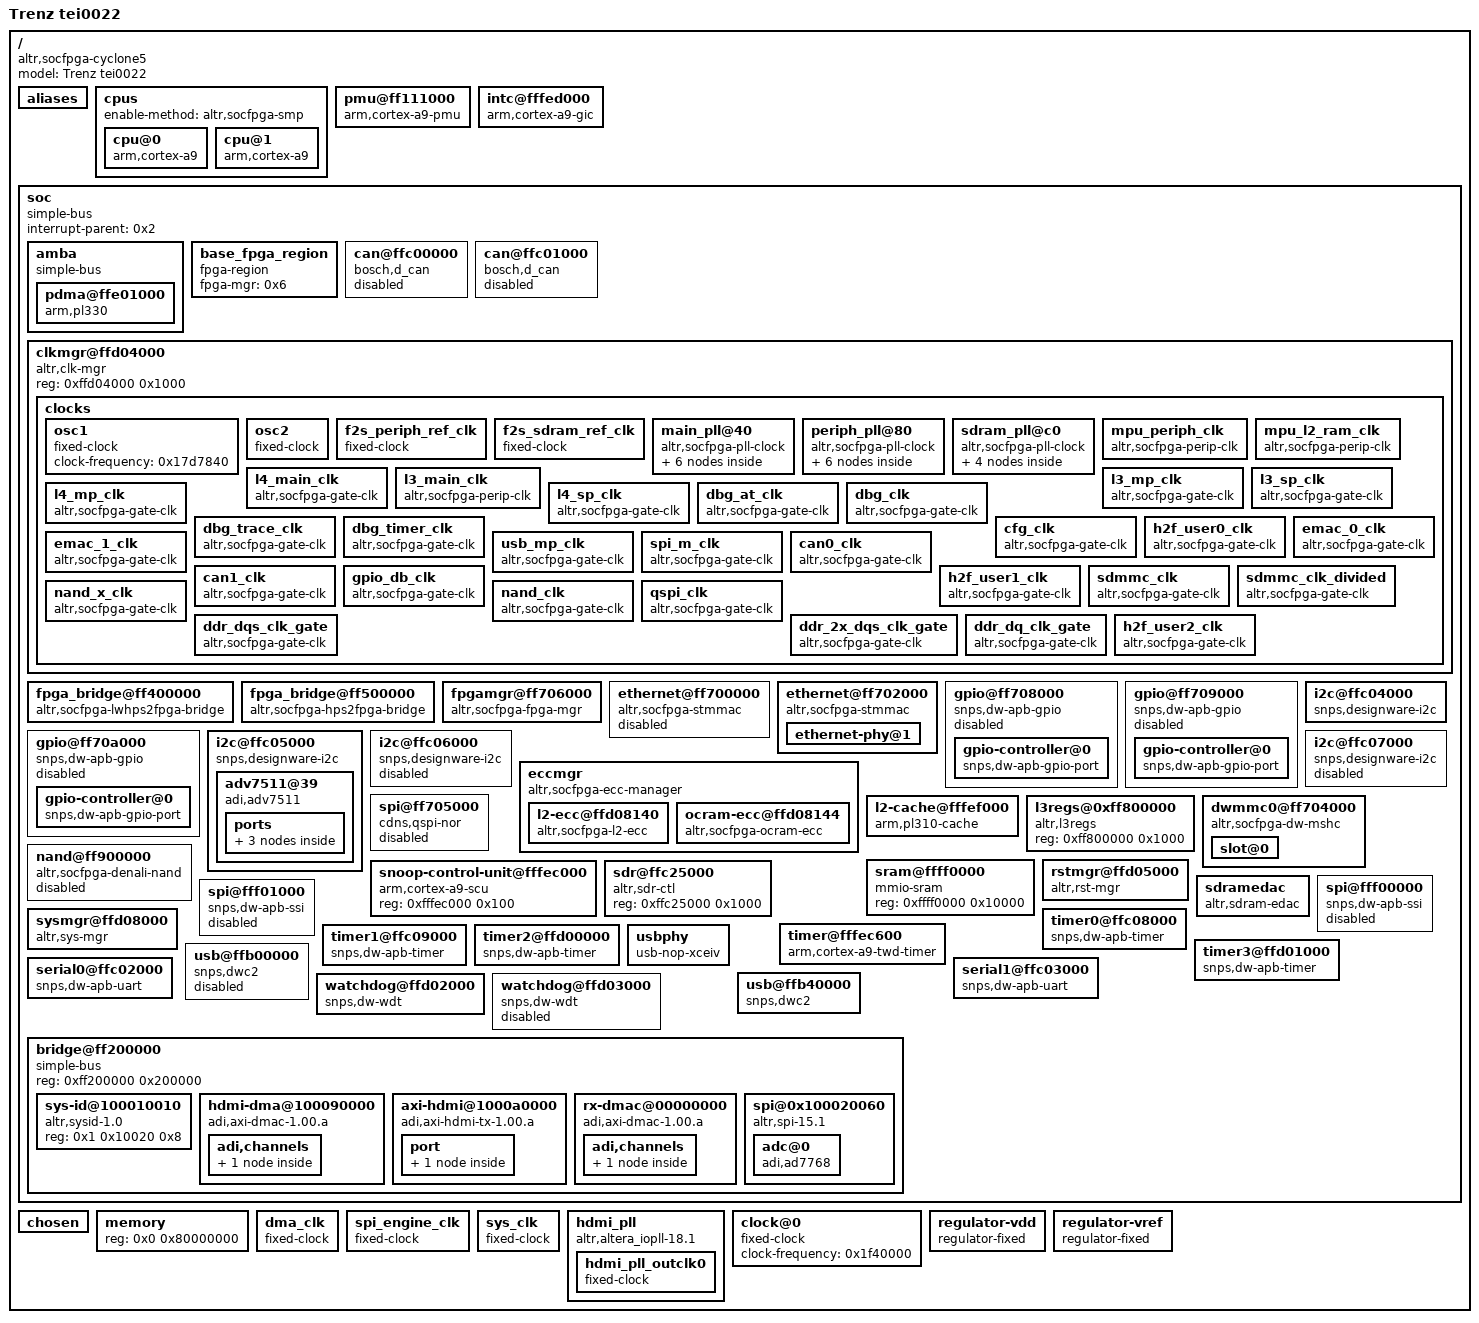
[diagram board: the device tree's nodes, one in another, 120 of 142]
/dts-v1/;

/memreserve/	0x0000000000000000 0x0000000000001000;
/ {
	#address-cells = <0x1>;
	#size-cells = <0x1>;
	model = "Trenz tei0022";
	compatible = "altr,socfpga-cyclone5", "altr,socfpga";

	aliases {
		ethernet0 = "/soc/ethernet@ff702000";
		ethernet1 = "/soc/ethernet@ff702000";
		serial0 = "/soc/serial0@ffc02000";
		serial1 = "/soc/serial1@ffc03000";
		timer0 = "/soc/timer0@ffc08000";
		timer1 = "/soc/timer1@ffc09000";
		timer2 = "/soc/timer2@ffd00000";
		timer3 = "/soc/timer3@ffd01000";
	};

	cpus {
		#address-cells = <0x1>;
		#size-cells = <0x0>;
		enable-method = "altr,socfpga-smp";

		cpu@0 {
			compatible = "arm,cortex-a9";
			device_type = "cpu";
			reg = <0x0>;
			next-level-cache = <0x1>;
			phandle = <0x3>;
		};

		cpu@1 {
			compatible = "arm,cortex-a9";
			device_type = "cpu";
			reg = <0x1>;
			next-level-cache = <0x1>;
			phandle = <0x4>;
		};
	};

	pmu@ff111000 {
		compatible = "arm,cortex-a9-pmu";
		interrupt-parent = <0x2>;
		interrupts = <0x0 0xb0 0x4 0x0 0xb1 0x4>;
		interrupt-affinity = <0x3 0x4>;
		reg = <0xff111000 0x1000 0xff113000 0x1000>;
	};

	intc@fffed000 {
		compatible = "arm,cortex-a9-gic";
		#interrupt-cells = <0x3>;
		interrupt-controller;
		reg = <0xfffed000 0x1000 0xfffec100 0x100>;
		phandle = <0x2>;
	};

	soc {
		#address-cells = <0x1>;
		#size-cells = <0x1>;
		compatible = "simple-bus";
		device_type = "soc";
		interrupt-parent = <0x2>;
		ranges;

		amba {
			compatible = "simple-bus";
			#address-cells = <0x1>;
			#size-cells = <0x1>;
			ranges;

			pdma@ffe01000 {
				compatible = "arm,pl330", "arm,primecell";
				reg = <0xffe01000 0x1000>;
				interrupts = <0x0 0x68 0x4 0x0 0x69 0x4 0x0 0x6a 0x4 0x0 0x6b 0x4 0x0 0x6c 0x4 0x0 0x6d 0x4 0x0 0x6e 0x4 0x0 0x6f 0x4>;
				#dma-cells = <0x1>;
				#dma-channels = <0x8>;
				#dma-requests = <0x20>;
				clocks = <0x5>;
				clock-names = "apb_pclk";
				phandle = <0x32>;
			};
		};

		base_fpga_region {
			compatible = "fpga-region";
			fpga-mgr = <0x6>;
			#address-cells = <0x1>;
			#size-cells = <0x1>;
		};

		can@ffc00000 {
			compatible = "bosch,d_can";
			reg = <0xffc00000 0x1000>;
			interrupts = <0x0 0x83 0x4 0x0 0x84 0x4 0x0 0x85 0x4 0x0 0x86 0x4>;
			clocks = <0x7>;
			status = "disabled";
		};

		can@ffc01000 {
			compatible = "bosch,d_can";
			reg = <0xffc01000 0x1000>;
			interrupts = <0x0 0x87 0x4 0x0 0x88 0x4 0x0 0x89 0x4 0x0 0x8a 0x4>;
			clocks = <0x8>;
			status = "disabled";
		};

		clkmgr@ffd04000 {
			compatible = "altr,clk-mgr";
			reg = <0xffd04000 0x1000>;

			clocks {
				#address-cells = <0x1>;
				#size-cells = <0x0>;

				osc1 {
					#clock-cells = <0x0>;
					compatible = "fixed-clock";
					clock-frequency = <0x17d7840>;
					phandle = <0x9>;
				};

				osc2 {
					#clock-cells = <0x0>;
					compatible = "fixed-clock";
					phandle = <0xb>;
				};

				f2s_periph_ref_clk {
					#clock-cells = <0x0>;
					compatible = "fixed-clock";
					phandle = <0xc>;
				};

				f2s_sdram_ref_clk {
					#clock-cells = <0x0>;
					compatible = "fixed-clock";
					phandle = <0xe>;
				};

				main_pll@40 {
					#address-cells = <0x1>;
					#size-cells = <0x0>;
					#clock-cells = <0x0>;
					compatible = "altr,socfpga-pll-clock";
					clocks = <0x9>;
					reg = <0x40>;
					phandle = <0xa>;

					mpuclk@48 {
						#clock-cells = <0x0>;
						compatible = "altr,socfpga-perip-clk";
						clocks = <0xa>;
						div-reg = <0xe0 0x0 0x9>;
						reg = <0x48>;
						phandle = <0x10>;
					};

					mainclk@4c {
						#clock-cells = <0x0>;
						compatible = "altr,socfpga-perip-clk";
						clocks = <0xa>;
						div-reg = <0xe4 0x0 0x9>;
						reg = <0x4c>;
						phandle = <0x11>;
					};

					dbg_base_clk@50 {
						#clock-cells = <0x0>;
						compatible = "altr,socfpga-perip-clk";
						clocks = <0xa 0x9>;
						div-reg = <0xe8 0x0 0x9>;
						reg = <0x50>;
						phandle = <0x14>;
					};

					main_qspi_clk@54 {
						#clock-cells = <0x0>;
						compatible = "altr,socfpga-perip-clk";
						clocks = <0xa>;
						reg = <0x54>;
						phandle = <0x1d>;
					};

					main_nand_sdmmc_clk@58 {
						#clock-cells = <0x0>;
						compatible = "altr,socfpga-perip-clk";
						clocks = <0xa>;
						reg = <0x58>;
						phandle = <0x1a>;
					};

					cfg_h2f_usr0_clk@5c {
						#clock-cells = <0x0>;
						compatible = "altr,socfpga-perip-clk";
						clocks = <0xa>;
						reg = <0x5c>;
						phandle = <0x16>;
					};
				};

				periph_pll@80 {
					#address-cells = <0x1>;
					#size-cells = <0x0>;
					#clock-cells = <0x0>;
					compatible = "altr,socfpga-pll-clock";
					clocks = <0x9 0xb 0xc>;
					reg = <0x80>;
					phandle = <0xd>;

					emac0_clk@88 {
						#clock-cells = <0x0>;
						compatible = "altr,socfpga-perip-clk";
						clocks = <0xd>;
						reg = <0x88>;
						phandle = <0x17>;
					};

					emac1_clk@8c {
						#clock-cells = <0x0>;
						compatible = "altr,socfpga-perip-clk";
						clocks = <0xd>;
						reg = <0x8c>;
						phandle = <0x18>;
					};

					per_qsi_clk@90 {
						#clock-cells = <0x0>;
						compatible = "altr,socfpga-perip-clk";
						clocks = <0xd>;
						reg = <0x90>;
						phandle = <0x1e>;
					};

					per_nand_mmc_clk@94 {
						#clock-cells = <0x0>;
						compatible = "altr,socfpga-perip-clk";
						clocks = <0xd>;
						reg = <0x94>;
						phandle = <0x1b>;
					};

					per_base_clk@98 {
						#clock-cells = <0x0>;
						compatible = "altr,socfpga-perip-clk";
						clocks = <0xd>;
						reg = <0x98>;
						phandle = <0x13>;
					};

					h2f_usr1_clk@9c {
						#clock-cells = <0x0>;
						compatible = "altr,socfpga-perip-clk";
						clocks = <0xd>;
						reg = <0x9c>;
						phandle = <0x19>;
					};
				};

				sdram_pll@c0 {
					#address-cells = <0x1>;
					#size-cells = <0x0>;
					#clock-cells = <0x0>;
					compatible = "altr,socfpga-pll-clock";
					clocks = <0x9 0xb 0xe>;
					reg = <0xc0>;
					phandle = <0xf>;

					ddr_dqs_clk@c8 {
						#clock-cells = <0x0>;
						compatible = "altr,socfpga-perip-clk";
						clocks = <0xf>;
						reg = <0xc8>;
						phandle = <0x1f>;
					};

					ddr_2x_dqs_clk@cc {
						#clock-cells = <0x0>;
						compatible = "altr,socfpga-perip-clk";
						clocks = <0xf>;
						reg = <0xcc>;
						phandle = <0x20>;
					};

					ddr_dq_clk@d0 {
						#clock-cells = <0x0>;
						compatible = "altr,socfpga-perip-clk";
						clocks = <0xf>;
						reg = <0xd0>;
						phandle = <0x21>;
					};

					h2f_usr2_clk@d4 {
						#clock-cells = <0x0>;
						compatible = "altr,socfpga-perip-clk";
						clocks = <0xf>;
						reg = <0xd4>;
						phandle = <0x22>;
					};
				};

				mpu_periph_clk {
					#clock-cells = <0x0>;
					compatible = "altr,socfpga-perip-clk";
					clocks = <0x10>;
					fixed-divider = <0x4>;
					phandle = <0x31>;
				};

				mpu_l2_ram_clk {
					#clock-cells = <0x0>;
					compatible = "altr,socfpga-perip-clk";
					clocks = <0x10>;
					fixed-divider = <0x2>;
				};

				l4_main_clk {
					#clock-cells = <0x0>;
					compatible = "altr,socfpga-gate-clk";
					clocks = <0x11>;
					clk-gate = <0x60 0x0>;
					phandle = <0x5>;
				};

				l3_main_clk {
					#clock-cells = <0x0>;
					compatible = "altr,socfpga-perip-clk";
					clocks = <0x11>;
					fixed-divider = <0x1>;
				};

				l3_mp_clk {
					#clock-cells = <0x0>;
					compatible = "altr,socfpga-gate-clk";
					clocks = <0x11>;
					div-reg = <0x64 0x0 0x2>;
					clk-gate = <0x60 0x1>;
					phandle = <0x12>;
				};

				l3_sp_clk {
					#clock-cells = <0x0>;
					compatible = "altr,socfpga-gate-clk";
					clocks = <0x12>;
					div-reg = <0x64 0x2 0x2>;
				};

				l4_mp_clk {
					#clock-cells = <0x0>;
					compatible = "altr,socfpga-gate-clk";
					clocks = <0x11 0x13>;
					div-reg = <0x64 0x4 0x3>;
					clk-gate = <0x60 0x2>;
					phandle = <0x27>;
				};

				l4_sp_clk {
					#clock-cells = <0x0>;
					compatible = "altr,socfpga-gate-clk";
					clocks = <0x11 0x13>;
					div-reg = <0x64 0x7 0x3>;
					clk-gate = <0x60 0x3>;
					phandle = <0x28>;
				};

				dbg_at_clk {
					#clock-cells = <0x0>;
					compatible = "altr,socfpga-gate-clk";
					clocks = <0x14>;
					div-reg = <0x68 0x0 0x2>;
					clk-gate = <0x60 0x4>;
					phandle = <0x15>;
				};

				dbg_clk {
					#clock-cells = <0x0>;
					compatible = "altr,socfpga-gate-clk";
					clocks = <0x15>;
					div-reg = <0x68 0x2 0x2>;
					clk-gate = <0x60 0x5>;
				};

				dbg_trace_clk {
					#clock-cells = <0x0>;
					compatible = "altr,socfpga-gate-clk";
					clocks = <0x14>;
					div-reg = <0x6c 0x0 0x3>;
					clk-gate = <0x60 0x6>;
				};

				dbg_timer_clk {
					#clock-cells = <0x0>;
					compatible = "altr,socfpga-gate-clk";
					clocks = <0x14>;
					clk-gate = <0x60 0x7>;
				};

				cfg_clk {
					#clock-cells = <0x0>;
					compatible = "altr,socfpga-gate-clk";
					clocks = <0x16>;
					clk-gate = <0x60 0x8>;
				};

				h2f_user0_clk {
					#clock-cells = <0x0>;
					compatible = "altr,socfpga-gate-clk";
					clocks = <0x16>;
					clk-gate = <0x60 0x9>;
				};

				emac_0_clk {
					#clock-cells = <0x0>;
					compatible = "altr,socfpga-gate-clk";
					clocks = <0x17>;
					clk-gate = <0xa0 0x0>;
					phandle = <0x25>;
				};

				emac_1_clk {
					#clock-cells = <0x0>;
					compatible = "altr,socfpga-gate-clk";
					clocks = <0x18>;
					clk-gate = <0xa0 0x1>;
					phandle = <0x26>;
				};

				usb_mp_clk {
					#clock-cells = <0x0>;
					compatible = "altr,socfpga-gate-clk";
					clocks = <0x13>;
					clk-gate = <0xa0 0x2>;
					div-reg = <0xa4 0x0 0x3>;
					phandle = <0x33>;
				};

				spi_m_clk {
					#clock-cells = <0x0>;
					compatible = "altr,socfpga-gate-clk";
					clocks = <0x13>;
					clk-gate = <0xa0 0x3>;
					div-reg = <0xa4 0x3 0x3>;
					phandle = <0x30>;
				};

				can0_clk {
					#clock-cells = <0x0>;
					compatible = "altr,socfpga-gate-clk";
					clocks = <0x13>;
					clk-gate = <0xa0 0x4>;
					div-reg = <0xa4 0x6 0x3>;
					phandle = <0x7>;
				};

				can1_clk {
					#clock-cells = <0x0>;
					compatible = "altr,socfpga-gate-clk";
					clocks = <0x13>;
					clk-gate = <0xa0 0x5>;
					div-reg = <0xa4 0x9 0x3>;
					phandle = <0x8>;
				};

				gpio_db_clk {
					#clock-cells = <0x0>;
					compatible = "altr,socfpga-gate-clk";
					clocks = <0x13>;
					clk-gate = <0xa0 0x6>;
					div-reg = <0xa8 0x0 0x18>;
				};

				h2f_user1_clk {
					#clock-cells = <0x0>;
					compatible = "altr,socfpga-gate-clk";
					clocks = <0x19>;
					clk-gate = <0xa0 0x7>;
				};

				sdmmc_clk {
					#clock-cells = <0x0>;
					compatible = "altr,socfpga-gate-clk";
					clocks = <0xc 0x1a 0x1b>;
					clk-gate = <0xa0 0x8>;
					clk-phase = <0x0 0x87>;
					phandle = <0x1c>;
				};

				sdmmc_clk_divided {
					#clock-cells = <0x0>;
					compatible = "altr,socfpga-gate-clk";
					clocks = <0x1c>;
					clk-gate = <0xa0 0x8>;
					fixed-divider = <0x4>;
					phandle = <0x2c>;
				};

				nand_x_clk {
					#clock-cells = <0x0>;
					compatible = "altr,socfpga-gate-clk";
					clocks = <0xc 0x1a 0x1b>;
					clk-gate = <0xa0 0x9>;
					phandle = <0x2d>;
				};

				nand_clk {
					#clock-cells = <0x0>;
					compatible = "altr,socfpga-gate-clk";
					clocks = <0xc 0x1a 0x1b>;
					clk-gate = <0xa0 0xa>;
					fixed-divider = <0x4>;
				};

				qspi_clk {
					#clock-cells = <0x0>;
					compatible = "altr,socfpga-gate-clk";
					clocks = <0xc 0x1d 0x1e>;
					clk-gate = <0xa0 0xb>;
					phandle = <0x2e>;
				};

				ddr_dqs_clk_gate {
					#clock-cells = <0x0>;
					compatible = "altr,socfpga-gate-clk";
					clocks = <0x1f>;
					clk-gate = <0xd8 0x0>;
				};

				ddr_2x_dqs_clk_gate {
					#clock-cells = <0x0>;
					compatible = "altr,socfpga-gate-clk";
					clocks = <0x20>;
					clk-gate = <0xd8 0x1>;
				};

				ddr_dq_clk_gate {
					#clock-cells = <0x0>;
					compatible = "altr,socfpga-gate-clk";
					clocks = <0x21>;
					clk-gate = <0xd8 0x2>;
				};

				h2f_user2_clk {
					#clock-cells = <0x0>;
					compatible = "altr,socfpga-gate-clk";
					clocks = <0x22>;
					clk-gate = <0xd8 0x3>;
				};
			};
		};

		fpga_bridge@ff400000 {
			compatible = "altr,socfpga-lwhps2fpga-bridge";
			reg = <0xff400000 0x100000>;
			resets = <0x23 0x61>;
			clocks = <0x5>;
		};

		fpga_bridge@ff500000 {
			compatible = "altr,socfpga-hps2fpga-bridge";
			reg = <0xff500000 0x10000>;
			resets = <0x23 0x60>;
			clocks = <0x5>;
		};

		fpgamgr@ff706000 {
			compatible = "altr,socfpga-fpga-mgr";
			reg = <0xff706000 0x1000 0xffb90000 0x4>;
			interrupts = <0x0 0xaf 0x4>;
			phandle = <0x6>;
		};

		ethernet@ff700000 {
			compatible = "altr,socfpga-stmmac", "snps,dwmac-3.70a", "snps,dwmac";
			altr,sysmgr-syscon = <0x24 0x60 0x0>;
			reg = <0xff700000 0x2000>;
			interrupts = <0x0 0x73 0x4>;
			interrupt-names = "macirq";
			mac-address = [00 00 00 00 00 00];
			clocks = <0x25>;
			clock-names = "stmmaceth";
			resets = <0x23 0x20>;
			reset-names = "stmmaceth";
			snps,multicast-filter-bins = <0x100>;
			snps,perfect-filter-entries = <0x80>;
			tx-fifo-depth = <0x1000>;
			rx-fifo-depth = <0x1000>;
			status = "disabled";
		};

		ethernet@ff702000 {
			compatible = "altr,socfpga-stmmac", "snps,dwmac-3.70a", "snps,dwmac";
			altr,sysmgr-syscon = <0x24 0x60 0x2>;
			reg = <0xff702000 0x2000>;
			interrupts = <0x0 0x78 0x4>;
			interrupt-names = "macirq";
			mac-address = [00 00 00 00 00 00];
			clocks = <0x26>;
			clock-names = "stmmaceth";
			resets = <0x23 0x21>;
			reset-names = "stmmaceth";
			snps,multicast-filter-bins = <0x100>;
			snps,perfect-filter-entries = <0x80>;
			tx-fifo-depth = <0x1000>;
			rx-fifo-depth = <0x1000>;
			status = "okay";
			#address-cells = <0x1>;
			#size-cells = <0x0>;
			phy-mode = "rgmii-id";

			ethernet-phy@1 {
				reg = <0x1>;
				adi,rx-internal-delay-ps = <0x7d0>;
				adi,tx-internal-delay-ps = <0x7d0>;
			};
		};

		gpio@ff708000 {
			#address-cells = <0x1>;
			#size-cells = <0x0>;
			compatible = "snps,dw-apb-gpio";
			reg = <0xff708000 0x1000>;
			clocks = <0x27>;
			status = "disabled";

			gpio-controller@0 {
				compatible = "snps,dw-apb-gpio-port";
				gpio-controller;
				#gpio-cells = <0x2>;
				snps,nr-gpios = <0x1d>;
				reg = <0x0>;
				interrupt-controller;
				#interrupt-cells = <0x2>;
				interrupts = <0x0 0xa4 0x4>;
			};
		};

		gpio@ff709000 {
			#address-cells = <0x1>;
			#size-cells = <0x0>;
			compatible = "snps,dw-apb-gpio";
			reg = <0xff709000 0x1000>;
			clocks = <0x27>;
			status = "disabled";

			gpio-controller@0 {
				compatible = "snps,dw-apb-gpio-port";
				gpio-controller;
				#gpio-cells = <0x2>;
				snps,nr-gpios = <0x1d>;
				reg = <0x0>;
				interrupt-controller;
				#interrupt-cells = <0x2>;
				interrupts = <0x0 0xa5 0x4>;
			};
		};

		gpio@ff70a000 {
			#address-cells = <0x1>;
			#size-cells = <0x0>;
			compatible = "snps,dw-apb-gpio";
			reg = <0xff70a000 0x1000>;
			clocks = <0x27>;
			status = "disabled";

			gpio-controller@0 {
				compatible = "snps,dw-apb-gpio-port";
				gpio-controller;
				#gpio-cells = <0x2>;
				snps,nr-gpios = <0x1b>;
				reg = <0x0>;
				interrupt-controller;
				#interrupt-cells = <0x2>;
				interrupts = <0x0 0xa6 0x4>;
			};
		};

		i2c@ffc04000 {
			#address-cells = <0x1>;
			#size-cells = <0x0>;
			compatible = "snps,designware-i2c";
			reg = <0xffc04000 0x1000>;
			resets = <0x23 0x2c>;
			clocks = <0x28>;
			interrupts = <0x0 0x9e 0x4>;
			status = "okay";
			speed-mode = <0x0>;
		};

		i2c@ffc05000 {
			#address-cells = <0x1>;
			#size-cells = <0x0>;
			compatible = "snps,designware-i2c";
			reg = <0xffc05000 0x1000>;
			resets = <0x23 0x2d>;
			clocks = <0x28>;
			interrupts = <0x0 0x9f 0x4>;
			status = "okay";
			speed-mode = <0x0>;

			adv7511@39 {
				compatible = "adi,adv7511";
				reg = <0x39 0x3f>;
				reg-names = "primary", "edid";
				adi,input-depth = <0x8>;
				adi,input-colorspace = "yuv422";
				adi,input-clock = "1x";
				adi,input-style = <0x1>;
				adi,input-justification = "right";
				adi,clock-delay = <0x0>;
				avdd-supply = <0x29>;
				dvdd-supply = <0x29>;
				pvdd-supply = <0x29>;
				dvdd-3v-supply = <0x29>;
				bgvdd-supply = <0x29>;
				status = "okay";

				ports {
					#address-cells = <0x1>;
					#size-cells = <0x0>;

					port@0 {
						reg = <0x0>;

						endpoint {
							remote-endpoint = <0x2a>;
							phandle = <0x38>;
						};
					};

					port@1 {
						reg = <0x1>;
					};
				};
			};
		};

		i2c@ffc06000 {
			#address-cells = <0x1>;
			#size-cells = <0x0>;
			compatible = "snps,designware-i2c";
			reg = <0xffc06000 0x1000>;
			resets = <0x23 0x2e>;
			clocks = <0x28>;
			interrupts = <0x0 0xa0 0x4>;
			status = "disabled";
		};

		i2c@ffc07000 {
			#address-cells = <0x1>;
			#size-cells = <0x0>;
			compatible = "snps,designware-i2c";
			reg = <0xffc07000 0x1000>;
			resets = <0x23 0x2f>;
			clocks = <0x28>;
			interrupts = <0x0 0xa1 0x4>;
			status = "disabled";
		};

		eccmgr {
			compatible = "altr,socfpga-ecc-manager";
			#address-cells = <0x1>;
			#size-cells = <0x1>;
			ranges;

			l2-ecc@ffd08140 {
				compatible = "altr,socfpga-l2-ecc";
				reg = <0xffd08140 0x4>;
				interrupts = <0x0 0x24 0x1 0x0 0x25 0x1>;
			};

			ocram-ecc@ffd08144 {
				compatible = "altr,socfpga-ocram-ecc";
				reg = <0xffd08144 0x4>;
				iram = <0x2b>;
				interrupts = <0x0 0xb2 0x1 0x0 0xb3 0x1>;
			};
		};

		l2-cache@fffef000 {
			compatible = "arm,pl310-cache";
			reg = <0xfffef000 0x1000>;
			interrupts = <0x0 0x26 0x4>;
			cache-unified;
			cache-level = <0x2>;
			arm,tag-latency = <0x1 0x1 0x1>;
			arm,data-latency = <0x2 0x1 0x1>;
			prefetch-data = <0x1>;
			prefetch-instr = <0x1>;
			arm,shared-override;
			arm,double-linefill = <0x1>;
			arm,double-linefill-incr = <0x0>;
			arm,double-linefill-wrap = <0x1>;
			arm,prefetch-drop = <0x0>;
			arm,prefetch-offset = <0x7>;
			phandle = <0x1>;
		};

		l3regs@0xff800000 {
			compatible = "altr,l3regs", "syscon";
			reg = <0xff800000 0x1000>;
		};

		dwmmc0@ff704000 {
			compatible = "altr,socfpga-dw-mshc";
			reg = <0xff704000 0x1000>;
			interrupts = <0x0 0x8b 0x4>;
			fifo-depth = <0x400>;
			#address-cells = <0x1>;
			#size-cells = <0x0>;
			clocks = <0x27 0x2c>;
			clock-names = "biu", "ciu";
			status = "okay";
			broken-cd;
			bus-width = <0x4>;
			cap-mmc-highspeed;
			cap-sd-highspeed;
			supports-highspeed;
			altr,dw-mshc-ciu-div = <0x3>;
			altr,dw-mshc-sdr-timing = <0x0 0x3>;

			slot@0 {
				reg = <0x0>;
				bus-width = <0x4>;
			};
		};

		nand@ff900000 {
			#address-cells = <0x1>;
			#size-cells = <0x1>;
			compatible = "altr,socfpga-denali-nand";
			reg = <0xff900000 0x100000 0xffb80000 0x10000>;
			reg-names = "nand_data", "denali_reg";
			interrupts = <0x0 0x90 0x4>;
			dma-mask = <0xffffffff>;
			clocks = <0x2d>;
			status = "disabled";
		};

		sram@ffff0000 {
			compatible = "mmio-sram";
			reg = <0xffff0000 0x10000>;
			phandle = <0x2b>;
		};

		spi@ff705000 {
			compatible = "cdns,qspi-nor";
			#address-cells = <0x1>;
			#size-cells = <0x0>;
			reg = <0xff705000 0x1000 0xffa00000 0x1000>;
			interrupts = <0x0 0x97 0x4>;
			cdns,fifo-depth = <0x80>;
			cdns,fifo-width = <0x4>;
			cdns,trigger-address = <0x0>;
			clocks = <0x2e>;
			status = "disabled";
		};

		rstmgr@ffd05000 {
			#reset-cells = <0x1>;
			compatible = "altr,rst-mgr";
			reg = <0xffd05000 0x1000>;
			altr,modrst-offset = <0x10>;
			phandle = <0x23>;
		};

		snoop-control-unit@fffec000 {
			compatible = "arm,cortex-a9-scu";
			reg = <0xfffec000 0x100>;
		};

		sdr@ffc25000 {
			compatible = "altr,sdr-ctl", "syscon";
			reg = <0xffc25000 0x1000>;
			phandle = <0x2f>;
		};

		sdramedac {
			compatible = "altr,sdram-edac";
			altr,sdr-syscon = <0x2f>;
			interrupts = <0x0 0x27 0x4>;
		};

		spi@fff00000 {
			compatible = "snps,dw-apb-ssi";
			#address-cells = <0x1>;
			#size-cells = <0x0>;
			reg = <0xfff00000 0x1000>;
			interrupts = <0x0 0x9a 0x4>;
			num-cs = <0x4>;
			clocks = <0x30>;
			status = "disabled";
		};

		spi@fff01000 {
			compatible = "snps,dw-apb-ssi";
			#address-cells = <0x1>;
			#size-cells = <0x0>;
			reg = <0xfff01000 0x1000>;
			interrupts = <0x0 0x9b 0x4>;
			num-cs = <0x4>;
			clocks = <0x30>;
			status = "disabled";
		};

		sysmgr@ffd08000 {
			compatible = "altr,sys-mgr", "syscon";
			reg = <0xffd08000 0x4000>;
			cpu1-start-addr = <0xffd080c4>;
			phandle = <0x24>;
		};

		timer@fffec600 {
			compatible = "arm,cortex-a9-twd-timer";
			reg = <0xfffec600 0x100>;
			interrupts = <0x1 0xd 0xf01>;
			clocks = <0x31>;
		};

		timer0@ffc08000 {
			compatible = "snps,dw-apb-timer";
			interrupts = <0x0 0xa7 0x4>;
			reg = <0xffc08000 0x1000>;
			clocks = <0x28>;
			clock-names = "timer";
			clock-frequency = <0x5f5e100>;
		};

		timer1@ffc09000 {
			compatible = "snps,dw-apb-timer";
			interrupts = <0x0 0xa8 0x4>;
			reg = <0xffc09000 0x1000>;
			clocks = <0x28>;
			clock-names = "timer";
			clock-frequency = <0x5f5e100>;
		};

		timer2@ffd00000 {
			compatible = "snps,dw-apb-timer";
			interrupts = <0x0 0xa9 0x4>;
			reg = <0xffd00000 0x1000>;
			clocks = <0x9>;
			clock-names = "timer";
			clock-frequency = <0x17d7840>;
		};

		timer3@ffd01000 {
			compatible = "snps,dw-apb-timer";
			interrupts = <0x0 0xaa 0x4>;
			reg = <0xffd01000 0x1000>;
			clocks = <0x9>;
			clock-names = "timer";
			clock-frequency = <0x17d7840>;
		};

		serial0@ffc02000 {
			compatible = "snps,dw-apb-uart";
			reg = <0xffc02000 0x1000>;
			interrupts = <0x0 0xa2 0x4>;
			reg-shift = <0x2>;
			reg-io-width = <0x4>;
			clocks = <0x28>;
			dmas = <0x32 0x1c 0x32 0x1d>;
			dma-names = "tx", "rx";
			clock-frequency = <0x5f5e100>;
		};

		serial1@ffc03000 {
			compatible = "snps,dw-apb-uart";
			reg = <0xffc03000 0x1000>;
			interrupts = <0x0 0xa3 0x4>;
			reg-shift = <0x2>;
			reg-io-width = <0x4>;
			clocks = <0x28>;
			dmas = <0x32 0x1e 0x32 0x1f>;
			dma-names = "tx", "rx";
			clock-frequency = <0x5f5e100>;
		};

		usbphy {
			#phy-cells = <0x0>;
			compatible = "usb-nop-xceiv";
			status = "okay";
			phandle = <0x34>;
		};

		usb@ffb00000 {
			compatible = "snps,dwc2";
			reg = <0xffb00000 0xffff>;
			interrupts = <0x0 0x7d 0x4>;
			clocks = <0x33>;
			clock-names = "otg";
			resets = <0x23 0x22>;
			reset-names = "dwc2";
			phys = <0x34>;
			phy-names = "usb2-phy";
			status = "disabled";
		};

		usb@ffb40000 {
			compatible = "snps,dwc2";
			reg = <0xffb40000 0xffff>;
			interrupts = <0x0 0x80 0x4>;
			clocks = <0x33>;
			clock-names = "otg";
			resets = <0x23 0x23>;
			reset-names = "dwc2";
			phys = <0x34>;
			phy-names = "usb2-phy";
			status = "okay";
			enable-dynamic-fifo = <0x1>;
			host-rx-fifo-size = <0xa00>;
			host-perio-tx-fifo-size = <0xa00>;
			host-nperio-tx-fifo-size = <0xa00>;
			dma-desc-enable = <0x0>;
			dr_mode = "host";
		};

		watchdog@ffd02000 {
			compatible = "snps,dw-wdt";
			reg = <0xffd02000 0x1000>;
			interrupts = <0x0 0xab 0x4>;
			clocks = <0x9>;
			status = "okay";
		};

		watchdog@ffd03000 {
			compatible = "snps,dw-wdt";
			reg = <0xffd03000 0x1000>;
			interrupts = <0x0 0xac 0x4>;
			clocks = <0x9>;
			status = "disabled";
		};

		bridge@ff200000 {
			compatible = "simple-bus";
			reg = <0xff200000 0x200000>;
			reg-names = "axi_h2f_lw";
			#address-cells = <0x2>;
			#size-cells = <0x1>;
			ranges = <0x1 0x0 0xff200000 0x800 0x1 0x20060 0xff220060 0x8 0x1 0x90000 0xff290000 0x800 0x1 0xa0000 0xff2a0000 0x10000>;

			sys-id@100010010 {
				compatible = "altr,sysid-1.0";
				reg = <0x1 0x10020 0x8>;
			};

			hdmi-dma@100090000 {
				compatible = "adi,axi-dmac-1.00.a";
				reg = <0x1 0x90000 0x800>;
				#dma-cells = <0x1>;
				interrupt-parent = <0x2>;
				interrupts = <0x0 0x2c 0x4>;
				clocks = <0x35 0x0>;
				status = "okay";
				phandle = <0x36>;

				adi,channels {
					#size-cells = <0x0>;
					#address-cells = <0x1>;

					dma-channel@0 {
						reg = <0x0>;
						adi,source-bus-width = <0x40>;
						adi,source-bus-type = <0x0>;
						adi,destination-bus-width = <0x40>;
						adi,destination-bus-type = <0x1>;
					};
				};
			};

			axi-hdmi@1000a0000 {
				compatible = "adi,axi-hdmi-tx-1.00.a";
				reg = <0x1 0xa0000 0x10000>;
				dmas = <0x36 0x0>;
				dma-names = "video";
				clocks = <0x37 0x0>;
				status = "okay";

				port {

					endpoint {
						remote-endpoint = <0x38>;
						phandle = <0x2a>;
					};
				};
			};

			rx-dmac@00000000 {
				compatible = "adi,axi-dmac-1.00.a";
				reg = <0x1 0x0 0x800>;
				interrupt-parent = <0x2>;
				interrupts = <0x0 0x28 0x4>;
				#dma-cells = <0x1>;
				clocks = <0x35>;
				phandle = <0x39>;

				adi,channels {
					#size-cells = <0x0>;
					#address-cells = <0x1>;

					dma-channel@0 {
						reg = <0x0>;
						adi,source-bus-width = <0x20>;
						adi,source-bus-type = <0x2>;
						adi,destination-bus-width = <0x20>;
						adi,destination-bus-type = <0x0>;
					};
				};
			};

			spi@0x100020060 {
				compatible = "altr,spi-15.1", "altr,spi-1.0";
				reg = <0x1 0x20060 0x20>;
				interrupt-parent = <0x2>;
				interrupts = <0x0 0x2d 0x4>;
				clocks = <0x35>;
				#address-cells = <0x1>;
				#size-cells = <0x0>;
				bus-num = <0x0>;
				num-chipselect = <0x1>;
				status = "okay";

				adc@0 {
					compatible = "adi,ad7768";
					reg = <0x0>;
					spi-max-frequency = <0xf4240>;
					dmas = <0x39 0x0>;
					dma-names = "rx";
					vref-supply = <0x3a>;
					clocks = <0x3b>;
					clock-names = "mclk";
				};
			};
		};
	};

	chosen {
		bootargs = "earlyprintk";
		stdout-path = "serial0:115200n8";
	};

	memory {
		device_type = "memory";
		reg = <0x0 0x80000000>;
	};

	dma_clk {
		#clock-cells = <0x0>;
		compatible = "fixed-clock";
		clock-frequency = <0x5f5e100>;
		clock-output-names = "dma_clock";
		phandle = <0x35>;
	};

	spi_engine_clk {
		#clock-cells = <0x0>;
		compatible = "fixed-clock";
		clock-frequency = <0x9ef21aa>;
		clock-output-names = "spi_engine_clock";
	};

	sys_clk {
		#clock-cells = <0x0>;
		compatible = "fixed-clock";
		clock-frequency = <0x4c4b400>;
		clock-output-names = "sys_clock";
	};

	hdmi_pll {
		compatible = "altr,altera_iopll-18.1";
		#clock-cells = <0x1>;
		phandle = <0x37>;

		hdmi_pll_outclk0 {
			compatible = "fixed-clock";
			#clock-cells = <0x0>;
			clock-frequency = <0x8d9ee20>;
			clock-output-names = "hdmi_pll-outclk0";
		};
	};

	clock@0 {
		#clock-cells = <0x0>;
		compatible = "fixed-clock";
		clock-frequency = <0x1f40000>;
		phandle = <0x3b>;
	};

	regulator-vdd {
		compatible = "regulator-fixed";
		regulator-name = "fixed-supply";
		regulator-min-microvolt = <0x325aa0>;
		regulator-max-microvolt = <0x325aa0>;
		regulator-always-on;
		phandle = <0x29>;
	};

	regulator-vref {
		compatible = "regulator-fixed";
		regulator-name = "fixed-supply";
		regulator-min-microvolt = <0x2625a0>;
		regulator-max-microvolt = <0x2625a0>;
		regulator-always-on;
		phandle = <0x3a>;
	};
};
